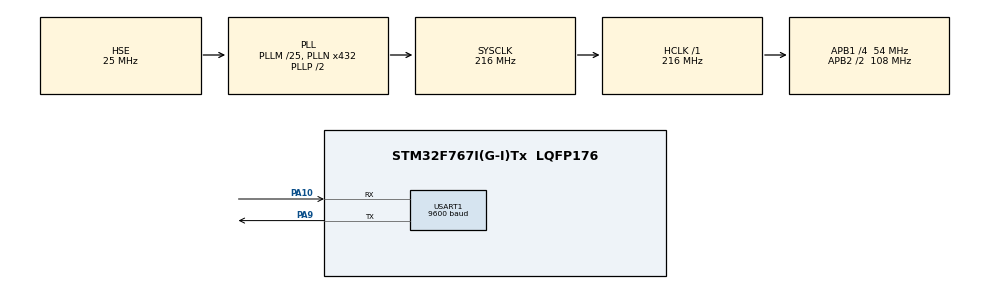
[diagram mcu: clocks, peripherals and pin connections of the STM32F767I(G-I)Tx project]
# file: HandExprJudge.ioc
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CORTEX_M7.CPU_DCache=Enabled
CORTEX_M7.CPU_ICache=Enabled
Mcu.Family=STM32F7
Mcu.Name=STM32F767I(G-I)Tx
Mcu.Package=LQFP176
NVIC.PriorityGroup=NVIC_PRIORITYGROUP_4
NVIC.USART1_IRQn=true\:1\:0\:true\:false\:true\:true\:true\:true
PA10.Mode=Asynchronous
PA10.Signal=USART1_RX
PA13.Mode=Serial_Wire
PA13.Signal=SYS_JTMS-SWDIO
PA14.Mode=Serial_Wire
PA14.Signal=SYS_JTCK-SWCLK
PA9.Mode=Asynchronous
PA9.Signal=USART1_TX
PH0/OSC_IN.Mode=HSE-External-Oscillator
PH0/OSC_IN.Signal=RCC_OSC_IN
PH1/OSC_OUT.Mode=HSE-External-Oscillator
PH1/OSC_OUT.Signal=RCC_OSC_OUT
ProjectManager.HeapSize=0x800
ProjectManager.StackSize=0x800
ProjectManager.TargetToolchain=MDK-ARM V5.27
RCC.AHBFreq_Value=216000000
RCC.APB1CLKDivider=RCC_HCLK_DIV4
RCC.APB1Freq_Value=54000000
RCC.APB1TimFreq_Value=108000000
RCC.APB2CLKDivider=RCC_HCLK_DIV2
RCC.APB2Freq_Value=108000000
RCC.APB2TimFreq_Value=216000000
RCC.CortexFreq_Value=216000000
RCC.HCLKFreq_Value=216000000
RCC.HSE_VALUE=25000000
RCC.HSI_VALUE=16000000
RCC.LSE_VALUE=32768
RCC.PLLM=25
RCC.PLLN=432
RCC.PLLSourceVirtual=RCC_PLLSOURCE_HSE
RCC.SYSCLKFreq_VALUE=216000000
RCC.SYSCLKSource=RCC_SYSCLKSOURCE_PLLCLK
RCC.USBFreq_Value=216000000
RCC.VCOOutputFreq_Value=432000000
USART1.BaudRate=9600
USART1.VirtualMode-Asynchronous=VM_ASYNC
VP_CRC_VS_CRC.Mode=CRC_Activate
board=custom

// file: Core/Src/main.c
/* USER CODE BEGIN Header */
/**
  ******************************************************************************
  * @file           : main.c
  * @brief          : Main program body
  ******************************************************************************
  * @attention
  *
  * Copyright (c) 2025 STMicroelectronics.
  * All rights reserved.
  *
  * This software is licensed under terms that can be found in the LICENSE file
  * in the root directory of this software component.
  * If no LICENSE file comes with this software, it is provided AS-IS.
  *
  ******************************************************************************
  */
/* USER CODE END Header */
#include "main.h"
#include "crc.h"
#include "usart.h"
#include "gpio.h"

/* USER CODE BEGIN Includes */
#include <stdio.h>
#include "app_controller.h"
/* USER CODE END Includes */

void SystemClock_Config(void);

/* USER CODE BEGIN 0 */
int fputc(int ch, FILE *f)
{
  (void)f;
  HAL_UART_Transmit(&huart1, (uint8_t *)&ch, 1, 0xffff);
  return ch;
}
/* USER CODE END 0 */

int main(void)
{
  /* USER CODE BEGIN 1 */
  char tx_buf[80];
  int tx_len = 0;
  /* USER CODE END 1 */

  /* Enable the CPU Cache */
  SCB_EnableICache();
  SCB_EnableDCache();

  /* MCU Configuration--------------------------------------------------------*/
  HAL_Init();

  SystemClock_Config();

  MX_GPIO_Init();
  MX_CRC_Init();
  MX_USART1_UART_Init();

  /* USER CODE BEGIN 2 */
  tx_len = sprintf(tx_buf, "STM32F7 Handwritten Expression Judge System\r\n");
  HAL_UART_Transmit(&huart1, (uint8_t *)tx_buf, tx_len, 200);
  tx_len = sprintf(tx_buf, "Ready. Send character image or expression payload.\r\n");
  HAL_UART_Transmit(&huart1, (uint8_t *)tx_buf, tx_len, 200);

  App_Init();
  HAL_UARTEx_ReceiveToIdle_IT(&huart1, App_RxBuffer(), App_RxBufferSize());
  /* USER CODE END 2 */

  /* Infinite loop */
  /* USER CODE BEGIN WHILE */
  while (1)
  {
    if (App_HasPendingFrame())
    {
      App_ProcessPendingFrame();
    }
    /* USER CODE END WHILE */

  }
}

void SystemClock_Config(void)
{
  RCC_OscInitTypeDef RCC_OscInitStruct = {0};
  RCC_ClkInitTypeDef RCC_ClkInitStruct = {0};

  /** Configure the main internal regulator output voltage
  */
  __HAL_RCC_PWR_CLK_ENABLE();
  __HAL_PWR_VOLTAGESCALING_CONFIG(PWR_REGULATOR_VOLTAGE_SCALE1);

  /** Initializes the RCC Oscillators according to the specified parameters
  * in the RCC_OscInitTypeDef structure.
  */
  RCC_OscInitStruct.OscillatorType = RCC_OSCILLATORTYPE_HSE;
  RCC_OscInitStruct.HSEState = RCC_HSE_ON;
  RCC_OscInitStruct.PLL.PLLState = RCC_PLL_ON;
  RCC_OscInitStruct.PLL.PLLSource = RCC_PLLSOURCE_HSE;
  RCC_OscInitStruct.PLL.PLLM = 25;
  RCC_OscInitStruct.PLL.PLLN = 432;
  RCC_OscInitStruct.PLL.PLLP = RCC_PLLP_DIV2;
  RCC_OscInitStruct.PLL.PLLQ = 2;
  RCC_OscInitStruct.PLL.PLLR = 2;
  if (HAL_RCC_OscConfig(&RCC_OscInitStruct) != HAL_OK)
  {
    Error_Handler();
  }

  /** Activate the Over-Drive mode
  */
  if (HAL_PWREx_EnableOverDrive() != HAL_OK)
  {
    Error_Handler();
  }

  /** Initializes the CPU, AHB and APB buses clocks
  */
  RCC_ClkInitStruct.ClockType = RCC_CLOCKTYPE_HCLK|RCC_CLOCKTYPE_SYSCLK
                              |RCC_CLOCKTYPE_PCLK1|RCC_CLOCKTYPE_PCLK2;
  RCC_ClkInitStruct.SYSCLKSource = RCC_SYSCLKSOURCE_PLLCLK;
  RCC_ClkInitStruct.AHBCLKDivider = RCC_SYSCLK_DIV1;
  RCC_ClkInitStruct.APB1CLKDivider = RCC_HCLK_DIV4;
  RCC_ClkInitStruct.APB2CLKDivider = RCC_HCLK_DIV2;

  if (HAL_RCC_ClockConfig(&RCC_ClkInitStruct, FLASH_LATENCY_7) != HAL_OK)
  {
    Error_Handler();
  }
}

/* USER CODE BEGIN 4 */
void HAL_UARTEx_RxEventCallback(UART_HandleTypeDef *huart, uint16_t Size)
{
  if (huart->Instance == USART1)
  {
    App_OnUartRxEvent(Size);
    HAL_UARTEx_ReceiveToIdle_IT(&huart1, App_RxBuffer(), App_RxBufferSize());
  }
}
/* USER CODE END 4 */

void Error_Handler(void)
{
  __disable_irq();
  while (1)
  {
  }
}

#ifdef USE_FULL_ASSERT
/**
  * @brief  Reports the name of the source file and the source line number
  *         where the assert_param error has occurred.
  * @param  file: pointer to the source file name
  * @param  line: assert_param error line source number
  * @retval None
  */
void assert_failed(uint8_t *file, uint32_t line)
{
  /* USER CODE BEGIN 6 */
  (void)file;
  (void)line;
  /* USER CODE END 6 */
}
#endif /* USE_FULL_ASSERT */
